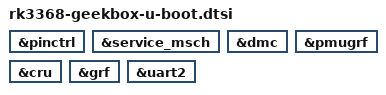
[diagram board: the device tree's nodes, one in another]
// SPDX-License-Identifier: GPL-2.0+ OR X11
/*
 * (C) Copyright 2017 Theobroma Systems Design und Consulting GmbH
 */

#include "rk3368-u-boot.dtsi"

&pinctrl {
	u-boot,dm-all;
};

&service_msch {
	u-boot,dm-all;
};

&dmc {
	u-boot,dm-all;
	status = "okay";
};

&pmugrf {
	u-boot,dm-all;
};

&cru {
	u-boot,dm-all;
};

&grf {
	u-boot,dm-all;
};

&uart2 {
	u-boot,dm-all;
};
